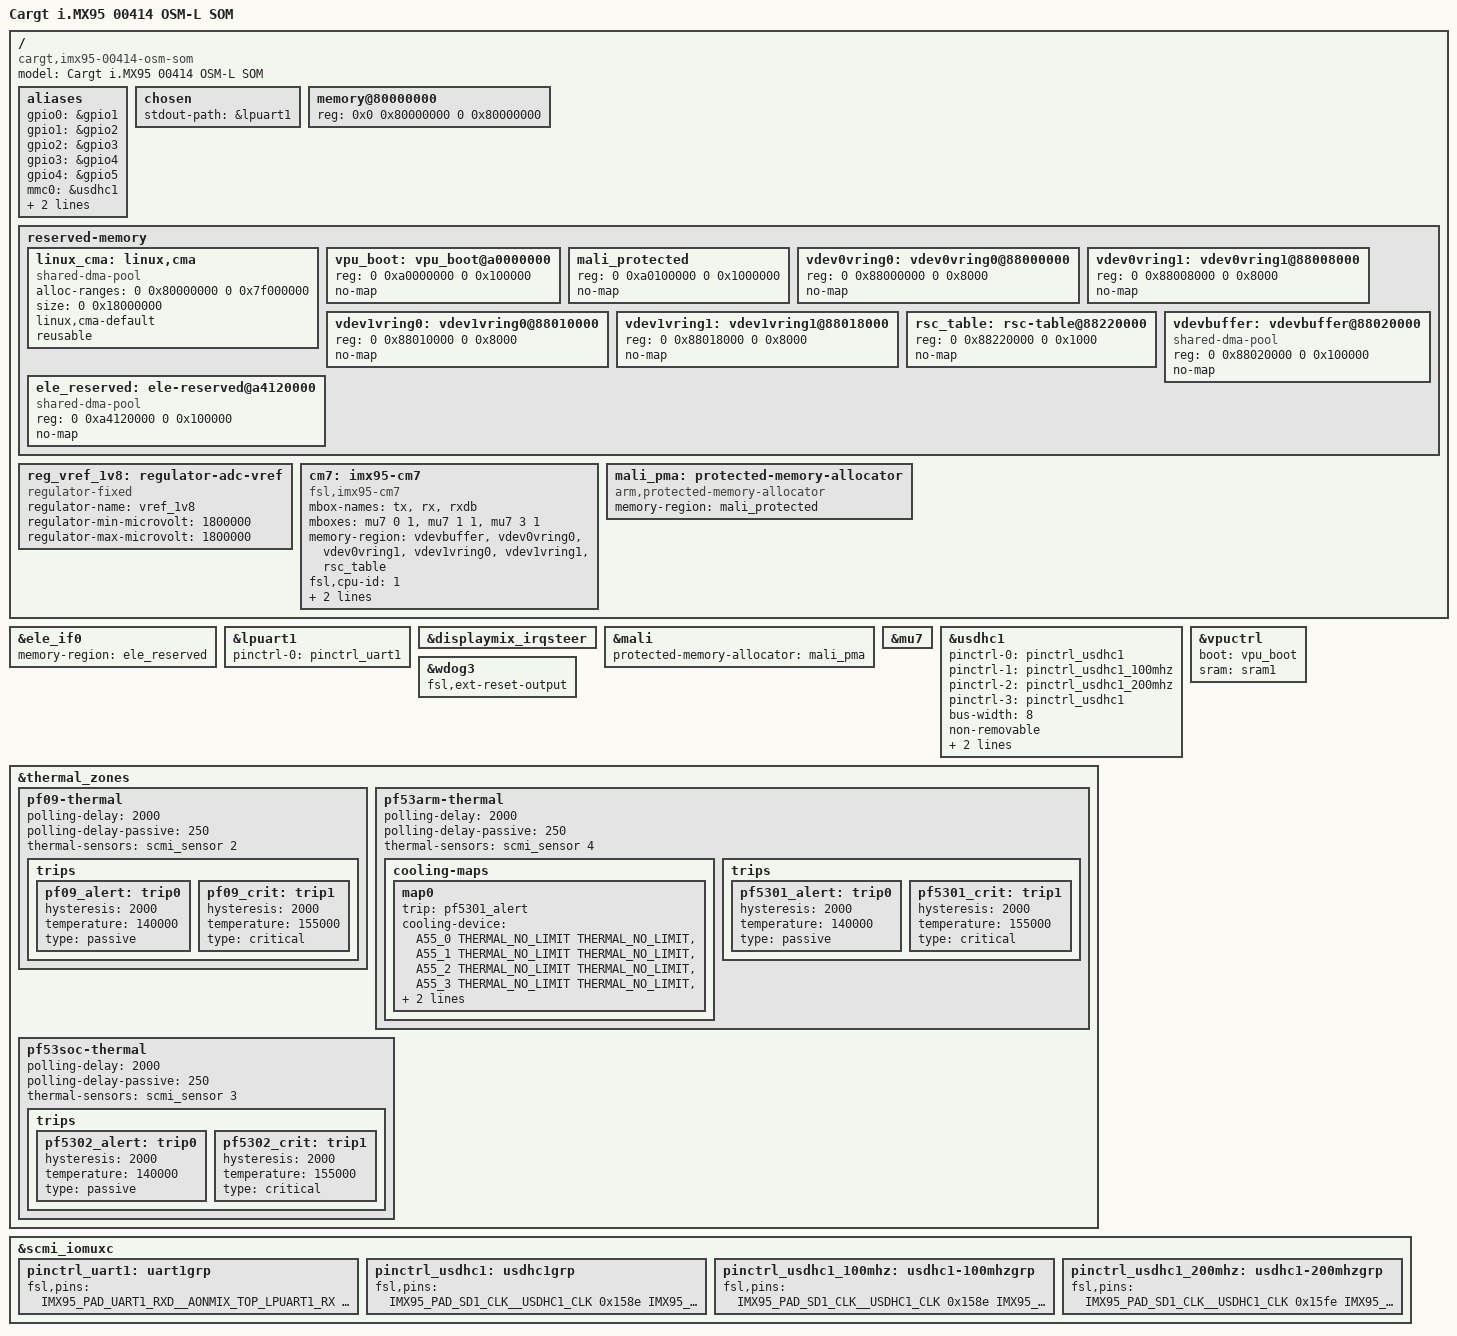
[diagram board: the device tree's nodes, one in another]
// SPDX-License-Identifier: (GPL-2.0+ OR MIT)
/*
 * Copyright 2024 NXP
 * Copyright 2026 Cargt
 *
 * Cargt i.MX 95 00414 OSM-L SOM (schematic 014-00414-00 rev 00).
 *
 * SOM-level hardware only. Carrier boards include this file and add the
 * peripherals routed to the OSM-L connector.
 *
 * On i.MX 95 the System Manager (SM, Cortex-M33) owns LPI2C1 and the
 * PF09 + PF5301 + PF5302 PMICs on it, so lpi2c1 is not enabled here. The
 * RX8111 RTC (0x32) and M24C02 EEPROM (0x50) share that bus and are
 * therefore not reachable from Linux directly.
 * TODO: expose RX8111 through an SM board RTC (SCMI BBM) or move it off
 *       LPI2C1 in a SOM respin.
 */

/dts-v1/;

#include "imx95.dtsi"

&ele_if0 {
	memory-region = <&ele_reserved>;
};

/ {
	model = "Cargt i.MX95 00414 OSM-L SOM";
	compatible = "cargt,imx95-00414-osm-som", "fsl,imx95";

	aliases {
		gpio0 = &gpio1;
		gpio1 = &gpio2;
		gpio2 = &gpio3;
		gpio3 = &gpio4;
		gpio4 = &gpio5;
		mmc0 = &usdhc1;
		mmc1 = &usdhc2;
		serial0 = &lpuart1;
	};

	chosen {
		stdout-path = &lpuart1;
	};

	/* Updated by U-Boot with the populated DDR size */
	memory@80000000 {
		device_type = "memory";
		reg = <0x0 0x80000000 0 0x80000000>;
	};

	reserved-memory {
		#address-cells = <2>;
		#size-cells = <2>;
		ranges;

		linux_cma: linux,cma {
			compatible = "shared-dma-pool";
			alloc-ranges = <0 0x80000000 0 0x7f000000>;
			/* 384 MB: the EVK 960 MB is too much for a 2 GB SOM */
			size = <0 0x18000000>;
			linux,cma-default;
			reusable;
		};

		vpu_boot: vpu_boot@a0000000 {
			reg = <0 0xa0000000 0 0x100000>;
			no-map;
		};

		mali_protected: mali_protected {
			reg = <0 0xa0100000 0 0x1000000>;
			no-map;
		};

		vdev0vring0: vdev0vring0@88000000 {
			reg = <0 0x88000000 0 0x8000>;
			no-map;
		};

		vdev0vring1: vdev0vring1@88008000 {
			reg = <0 0x88008000 0 0x8000>;
			no-map;
		};

		vdev1vring0: vdev1vring0@88010000 {
			reg = <0 0x88010000 0 0x8000>;
			no-map;
		};

		vdev1vring1: vdev1vring1@88018000 {
			reg = <0 0x88018000 0 0x8000>;
			no-map;
		};

		rsc_table: rsc-table@88220000 {
			reg = <0 0x88220000 0 0x1000>;
			no-map;
		};

		vdevbuffer: vdevbuffer@88020000 {
			compatible = "shared-dma-pool";
			reg = <0 0x88020000 0 0x100000>;
			no-map;
		};

		ele_reserved: ele-reserved@a4120000 {
			compatible = "shared-dma-pool";
			reg = <0 0xa4120000 0 0x100000>;
			no-map;
		};
	};

	/* ADC reference (VDD_1V8 on the SOM) */
	reg_vref_1v8: regulator-adc-vref {
		compatible = "regulator-fixed";
		regulator-name = "vref_1v8";
		regulator-min-microvolt = <1800000>;
		regulator-max-microvolt = <1800000>;
	};

	cm7: imx95-cm7 {
		compatible = "fsl,imx95-cm7";
		mbox-names = "tx", "rx", "rxdb";
		mboxes = <&mu7 0 1
			  &mu7 1 1
			  &mu7 3 1>;
		memory-region = <&vdevbuffer>, <&vdev0vring0>, <&vdev0vring1>,
				<&vdev1vring0>, <&vdev1vring1>, <&rsc_table>;
		/* cpuid and lmmid must align with SM firmware */
		fsl,cpu-id = <1>;
		fsl,lmm-id = <1>;
		fsl,startup-delay-ms = <50>;
		status = "okay";
	};

	mali_pma: protected-memory-allocator {
		compatible = "arm,protected-memory-allocator";
		memory-region = <&mali_protected>;
	};
};

&lpuart1 {
	/* OSM UART_CON (console) */
	pinctrl-names = "default";
	pinctrl-0 = <&pinctrl_uart1>;
	status = "okay";
};

/*
 * Display-mix interrupt steering: the DPU and the pixel interleaver take
 * their interrupts from it, so every display variant needs it. Enabled in
 * the NXP EVK base DT as well.
 */
&displaymix_irqsteer {
	status = "okay";
};

&mali {
	protected-memory-allocator = <&mali_pma>;
};

&mu7 {
	status = "okay";
};

&usdhc1 {
	/* 32 GB eMMC (MTFC32GBCAQTC) */
	pinctrl-names = "default", "state_100mhz", "state_200mhz", "sleep";
	pinctrl-0 = <&pinctrl_usdhc1>;
	pinctrl-1 = <&pinctrl_usdhc1_100mhz>;
	pinctrl-2 = <&pinctrl_usdhc1_200mhz>;
	pinctrl-3 = <&pinctrl_usdhc1>;
	bus-width = <8>;
	non-removable;
	no-sdio;
	no-sd;
	status = "okay";
};

&vpuctrl {
	boot = <&vpu_boot>;
	sram = <&sram1>;
};

&wdog3 {
	/* WDOG_ANY -> PF09 WDI */
	fsl,ext-reset-output;
	status = "okay";
};

&thermal_zones {
	pf09-thermal {
		polling-delay = <2000>;
		polling-delay-passive = <250>;
		thermal-sensors = <&scmi_sensor 2>;

		trips {
			pf09_alert: trip0 {
				hysteresis = <2000>;
				temperature = <140000>;
				type = "passive";
			};

			pf09_crit: trip1 {
				hysteresis = <2000>;
				temperature = <155000>;
				type = "critical";
			};
		};
	};

	pf53arm-thermal {
		polling-delay = <2000>;
		polling-delay-passive = <250>;
		thermal-sensors = <&scmi_sensor 4>;

		cooling-maps {
			map0 {
				trip = <&pf5301_alert>;
				cooling-device =
					<&A55_0 THERMAL_NO_LIMIT THERMAL_NO_LIMIT>,
					<&A55_1 THERMAL_NO_LIMIT THERMAL_NO_LIMIT>,
					<&A55_2 THERMAL_NO_LIMIT THERMAL_NO_LIMIT>,
					<&A55_3 THERMAL_NO_LIMIT THERMAL_NO_LIMIT>,
					<&A55_4 THERMAL_NO_LIMIT THERMAL_NO_LIMIT>,
					<&A55_5 THERMAL_NO_LIMIT THERMAL_NO_LIMIT>;
			};
		};

		trips {
			pf5301_alert: trip0 {
				hysteresis = <2000>;
				temperature = <140000>;
				type = "passive";
			};

			pf5301_crit: trip1 {
				hysteresis = <2000>;
				temperature = <155000>;
				type = "critical";
			};
		};
	};

	pf53soc-thermal {
		polling-delay = <2000>;
		polling-delay-passive = <250>;
		thermal-sensors = <&scmi_sensor 3>;

		trips {
			pf5302_alert: trip0 {
				hysteresis = <2000>;
				temperature = <140000>;
				type = "passive";
			};

			pf5302_crit: trip1 {
				hysteresis = <2000>;
				temperature = <155000>;
				type = "critical";
			};
		};
	};
};

&scmi_iomuxc {
	pinctrl_uart1: uart1grp {
		fsl,pins = <
			IMX95_PAD_UART1_RXD__AONMIX_TOP_LPUART1_RX		0x31e
			IMX95_PAD_UART1_TXD__AONMIX_TOP_LPUART1_TX		0x31e
		>;
	};

	pinctrl_usdhc1: usdhc1grp {
		fsl,pins = <
			IMX95_PAD_SD1_CLK__USDHC1_CLK			0x158e
			IMX95_PAD_SD1_CMD__USDHC1_CMD			0x138e
			IMX95_PAD_SD1_DATA0__USDHC1_DATA0		0x138e
			IMX95_PAD_SD1_DATA1__USDHC1_DATA1		0x138e
			IMX95_PAD_SD1_DATA2__USDHC1_DATA2		0x138e
			IMX95_PAD_SD1_DATA3__USDHC1_DATA3		0x138e
			IMX95_PAD_SD1_DATA4__USDHC1_DATA4		0x138e
			IMX95_PAD_SD1_DATA5__USDHC1_DATA5		0x138e
			IMX95_PAD_SD1_DATA6__USDHC1_DATA6		0x138e
			IMX95_PAD_SD1_DATA7__USDHC1_DATA7		0x138e
			IMX95_PAD_SD1_STROBE__USDHC1_STROBE		0x158e
		>;
	};

	pinctrl_usdhc1_100mhz: usdhc1-100mhzgrp {
		fsl,pins = <
			IMX95_PAD_SD1_CLK__USDHC1_CLK			0x158e
			IMX95_PAD_SD1_CMD__USDHC1_CMD			0x138e
			IMX95_PAD_SD1_DATA0__USDHC1_DATA0		0x138e
			IMX95_PAD_SD1_DATA1__USDHC1_DATA1		0x138e
			IMX95_PAD_SD1_DATA2__USDHC1_DATA2		0x138e
			IMX95_PAD_SD1_DATA3__USDHC1_DATA3		0x138e
			IMX95_PAD_SD1_DATA4__USDHC1_DATA4		0x138e
			IMX95_PAD_SD1_DATA5__USDHC1_DATA5		0x138e
			IMX95_PAD_SD1_DATA6__USDHC1_DATA6		0x138e
			IMX95_PAD_SD1_DATA7__USDHC1_DATA7		0x138e
			IMX95_PAD_SD1_STROBE__USDHC1_STROBE		0x158e
		>;
	};

	pinctrl_usdhc1_200mhz: usdhc1-200mhzgrp {
		fsl,pins = <
			IMX95_PAD_SD1_CLK__USDHC1_CLK			0x15fe
			IMX95_PAD_SD1_CMD__USDHC1_CMD			0x13fe
			IMX95_PAD_SD1_DATA0__USDHC1_DATA0		0x13fe
			IMX95_PAD_SD1_DATA1__USDHC1_DATA1		0x13fe
			IMX95_PAD_SD1_DATA2__USDHC1_DATA2		0x13fe
			IMX95_PAD_SD1_DATA3__USDHC1_DATA3		0x13fe
			IMX95_PAD_SD1_DATA4__USDHC1_DATA4		0x13fe
			IMX95_PAD_SD1_DATA5__USDHC1_DATA5		0x13fe
			IMX95_PAD_SD1_DATA6__USDHC1_DATA6		0x13fe
			IMX95_PAD_SD1_DATA7__USDHC1_DATA7		0x13fe
			IMX95_PAD_SD1_STROBE__USDHC1_STROBE		0x15fe
		>;
	};
};
